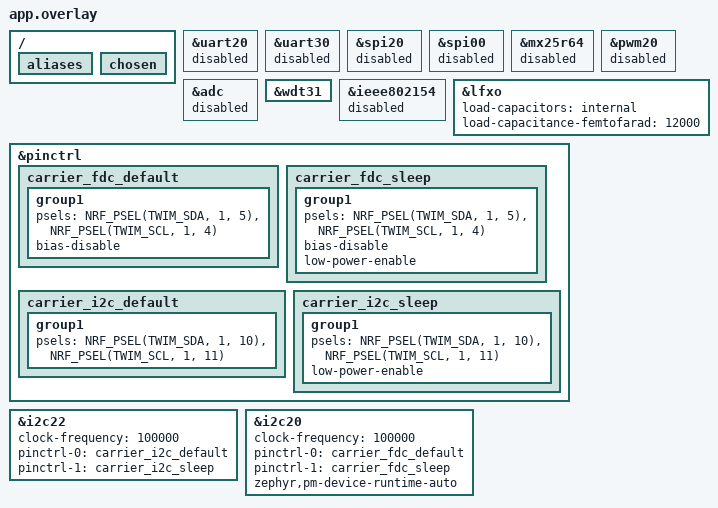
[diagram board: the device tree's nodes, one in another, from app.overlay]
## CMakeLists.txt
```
cmake_minimum_required(VERSION 3.20.0)
find_package(Zephyr REQUIRED HINTS $ENV{ZEPHYR_BASE})

# Production builds must opt in with a real signing key. The normal developer
# build intentionally keeps the SDK key so local builds remain reproducible,
# but this gate prevents that key from being used with the production profile.
if(DEFINED ENV{SENSOR_PRODUCTION_BUILD})
  if(NOT DEFINED CONFIG_MCUBOOT_SIGNATURE_KEY_FILE OR
     CONFIG_MCUBOOT_SIGNATURE_KEY_FILE STREQUAL "" OR
     CONFIG_MCUBOOT_SIGNATURE_KEY_FILE MATCHES "root-(rsa(-[0-9]+)?|ec(-p[0-9]+)?|ed25519)\\.pem$")
    message(FATAL_ERROR
      "SENSOR_PRODUCTION_BUILD requires CONFIG_MCUBOOT_SIGNATURE_KEY_FILE "
      "pointing to a protected non-SDK signing key")
  endif()
endif()

project(board_sensor)
target_sources(app PRIVATE src/main.c src/carrier.c src/bthome.c src/config.c src/config_service.c)
```

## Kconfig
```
mainmenu "Board sensor firmware"

source "Kconfig.zephyr"

config SENSOR_DEVELOPMENT
	bool "Development mode"
	default n
	help
		Use a short measurement cadence and a longer advertising window for bench work.

config SENSOR_CYCLE_SECONDS
	int "Normal measurement interval in seconds"
	default 60 if SENSOR_DEVELOPMENT
	default 900
	range 60 86400

config SENSOR_LOW_BATTERY_MV
	int "Low-battery threshold in millivolts"
	default 2500
	range 800 3300

config SENSOR_LOW_BATTERY_CYCLE_SECONDS
	int "Low-battery measurement interval in seconds"
	default 3600
	range 60 604800

config SENSOR_UV_RETRY_SECONDS
	int "Undervoltage/fault hibernate retry interval in seconds"
	default 60
	range 60 86400
	help
		Check recovery separately from the hourly low-battery measurement
		cadence. MCUboot checks voltage before image verification, sensing,
		or radio work; a restored supply must not remain silent for an hour.

config SENSOR_ADV_WINDOW_MS
	int "BLE advertising window in milliseconds"
	default 10000 if SENSOR_DEVELOPMENT
	default 5000
	range 5000 300000

config SENSOR_DEBUG_HOLD
	bool "Hold after measurement for debugger diagnostics"
	default n
	help
		Keep the CPU awake after the measurement so RTT can be read during bench work.

config SENSOR_OTA
	bool "Enable OTA maintenance image"
	default n
	help
		Build the MCUboot/MCUmgr maintenance image for the board. It keeps
		the boost rail in forced high-power mode, advertises a connectable SMP
		service, and stays awake for the update. Keep disabled in the normal
		battery beacon image.

config SENSOR_MOISTURE_CALIBRATED
	bool "Enable calibrated BTHome moisture objects"
	default y
	help
		Use the configured dry and wet single-ended capacitance endpoints.
		Leave disabled until the probe has been measured dry and wet.

config SENSOR_SENSE1_DRY_FF
	int "Dry SENSE1 capacitance in femtofarads"
	default 2655

config SENSOR_SENSE1_WET_FF
	int "Wet SENSE1 capacitance in femtofarads"
	default 5658

config SENSOR_SENSE2_DRY_FF
	int "Dry SENSE2 capacitance in femtofarads"
	default 2618

config SENSOR_SENSE2_WET_FF
	int "Wet SENSE2 capacitance in femtofarads"
	default 5571

config SENSOR_ADV_INTERVAL_MS
	int "Advertising event interval in milliseconds (multiple of 5)"
	default 500
	range 100 5000

config SENSOR_SESSION_SECONDS
	int "Maximum connected session duration in seconds"
	default 300
	range 30 900
```

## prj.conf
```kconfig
CONFIG_I2C=y
CONFIG_I2C_NRFX_TRANSFER_TIMEOUT=25
CONFIG_GPIO=y
CONFIG_WATCHDOG=y
CONFIG_REBOOT=y
CONFIG_POWEROFF=y
CONFIG_BT=y
CONFIG_BT_BROADCASTER=y
CONFIG_BT_PERIPHERAL=y
CONFIG_BT_OBSERVER=n
CONFIG_BT_DEVICE_NAME="Soil"

# The deployed sensor remains OTA-capable. A BLE connection during the normal
# advertising window holds the device awake while MCUmgr uploads the next
# signed image; an unconnected wake still returns to System OFF.
CONFIG_BOOTLOADER_MCUBOOT=y
CONFIG_FLASH=y
CONFIG_FLASH_MAP=y
CONFIG_STREAM_FLASH=y
CONFIG_IMG_MANAGER=y
CONFIG_MCUBOOT_IMG_MANAGER=y
CONFIG_MCUMGR=y
CONFIG_ZCBOR=y
CONFIG_MCUMGR_GRP_IMG=y
CONFIG_MCUMGR_GRP_OS=y
CONFIG_MCUMGR_TRANSPORT_BT=y
CONFIG_MCUMGR_TRANSPORT_BT_CONN_PARAM_CONTROL=y
CONFIG_MCUMGR_TRANSPORT_BT_REASSEMBLY=y
CONFIG_MCUMGR_TRANSPORT_NETBUF_SIZE=2475
CONFIG_MCUMGR_TRANSPORT_WORKQUEUE_STACK_SIZE=4608
CONFIG_BT_L2CAP_TX_MTU=498
CONFIG_BT_BUF_ACL_RX_SIZE=502
CONFIG_BT_BUF_ACL_TX_SIZE=502
CONFIG_BT_CTLR_DATA_LENGTH_MAX=251
CONFIG_SYSTEM_WORKQUEUE_STACK_SIZE=2304
CONFIG_HWINFO=y
CONFIG_SERIAL=n
CONFIG_UART_CONSOLE=n
CONFIG_MAIN_STACK_SIZE=2048
CONFIG_PM_DEVICE=y
CONFIG_PM_DEVICE_RUNTIME=y

# Configuration occupies the old 4 KB tail gap; MCUboot slots do not move.
CONFIG_ZMS=y
CONFIG_ZMS_DATA_CRC=y
CONFIG_BT_DEVICE_NAME_DYNAMIC=y
CONFIG_BT_DEVICE_NAME_MAX=11
CONFIG_BT_MAX_CONN=1
```

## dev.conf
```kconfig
CONFIG_SENSOR_DEVELOPMENT=y
CONFIG_SENSOR_CYCLE_SECONDS=60
CONFIG_SENSOR_ADV_WINDOW_MS=300000
CONFIG_SENSOR_MOISTURE_CALIBRATED=y
CONFIG_SENSOR_DEBUG_HOLD=n
CONFIG_BOOTLOADER_MCUBOOT=y
CONFIG_FLASH=y
CONFIG_FLASH_MAP=y
CONFIG_STREAM_FLASH=y
CONFIG_IMG_MANAGER=y
CONFIG_MCUBOOT_IMG_MANAGER=y
```

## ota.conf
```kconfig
CONFIG_SENSOR_OTA=y
CONFIG_MCUBOOT_IMGTOOL_SIGN_VERSION="0.2.6"
CONFIG_BOOTLOADER_MCUBOOT=y
CONFIG_FLASH=y
CONFIG_FLASH_MAP=y
CONFIG_IMG_MANAGER=y

CONFIG_BT=y
CONFIG_BT_PERIPHERAL=y
CONFIG_BT_BROADCASTER=y
CONFIG_BT_DEVICE_NAME="Soil-OTA"

CONFIG_NET_BUF=y
CONFIG_ZCBOR=y
CONFIG_CRC=y
CONFIG_STREAM_FLASH=y
CONFIG_MCUMGR=y
CONFIG_MCUMGR_GRP_IMG=y
CONFIG_MCUMGR_GRP_OS=y
CONFIG_MCUMGR_TRANSPORT_BT=y
CONFIG_MCUMGR_TRANSPORT_BT_CONN_PARAM_CONTROL=y
CONFIG_MCUMGR_TRANSPORT_BT_REASSEMBLY=y
CONFIG_MCUMGR_TRANSPORT_NETBUF_SIZE=2475
CONFIG_MCUMGR_TRANSPORT_WORKQUEUE_STACK_SIZE=4608

CONFIG_BT_L2CAP_TX_MTU=498
CONFIG_BT_BUF_ACL_RX_SIZE=502
CONFIG_BT_BUF_ACL_TX_SIZE=502
CONFIG_BT_CTLR_DATA_LENGTH_MAX=251
CONFIG_SYSTEM_WORKQUEUE_STACK_SIZE=2304
CONFIG_MAIN_STACK_SIZE=3072
CONFIG_LOG=y
CONFIG_LOG_MAX_LEVEL=3
```

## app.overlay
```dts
#include <zephyr/dt-bindings/pinctrl/nrf-pinctrl.h>
/ {
 /delete-node/ leds;
 /delete-node/ buttons;
 /delete-node/ pwmleds;
 aliases {
  /delete-property/ led0;
  /delete-property/ led1;
  /delete-property/ led2;
  /delete-property/ led3;
  /delete-property/ pwm-led0;
  /delete-property/ sw0;
  /delete-property/ sw1;
  /delete-property/ sw2;
  /delete-property/ sw3;
  /delete-property/ mcuboot-button0;
  /delete-property/ mcuboot-led0;
 };
 chosen {
  /delete-property/ zephyr,console;
  /delete-property/ zephyr,shell-uart;
  /delete-property/ zephyr,uart-mcumgr;
  /delete-property/ zephyr,bt-mon-uart;
  /delete-property/ zephyr,bt-c2h-uart;
 };
};
&uart20 { status = "disabled"; };
&uart30 { status = "disabled"; };
&spi20 { status = "disabled"; };
&spi00 { status = "disabled"; };
&mx25r64 { status = "disabled"; };
&pwm20 { status = "disabled"; };
&adc { status = "disabled"; };
&wdt31 { status = "okay"; };
&ieee802154 { status = "disabled"; };
&lfxo {
 load-capacitors = "internal";
 /* X1 CL=7 pF; provisional pin load, verify frequency on hardware. */
 load-capacitance-femtofarad = <12000>;
};
&pinctrl {
 carrier_fdc_default: carrier_fdc_default {
  group1 {
   psels = <NRF_PSEL(TWIM_SDA, 1, 5)>, <NRF_PSEL(TWIM_SCL, 1, 4)>;
   bias-disable;
  };
 };
 carrier_fdc_sleep: carrier_fdc_sleep {
  group1 {
   psels = <NRF_PSEL(TWIM_SDA, 1, 5)>, <NRF_PSEL(TWIM_SCL, 1, 4)>;
   bias-disable;
   low-power-enable;
  };
 };
 carrier_i2c_default: carrier_i2c_default {
  group1 { psels = <NRF_PSEL(TWIM_SDA, 1, 10)>, <NRF_PSEL(TWIM_SCL, 1, 11)>; };
 };
 carrier_i2c_sleep: carrier_i2c_sleep {
  group1 {
   psels = <NRF_PSEL(TWIM_SDA, 1, 10)>, <NRF_PSEL(TWIM_SCL, 1, 11)>;
   low-power-enable;
  };
 };
};
&i2c22 {
 status = "okay";
 clock-frequency = <100000>;
 pinctrl-0 = <&carrier_i2c_default>;
 pinctrl-1 = <&carrier_i2c_sleep>;
 pinctrl-names = "default", "sleep";
};

/* R36/R37 pull up only to +3V3_FDC_SW. Start suspended and release pins
 * between transfers, including failed transfers and before rail shutdown. */
&i2c20 {
 status = "okay";
 clock-frequency = <100000>;
 pinctrl-0 = <&carrier_fdc_default>;
 pinctrl-1 = <&carrier_fdc_sleep>;
 pinctrl-names = "default", "sleep";
 zephyr,pm-device-runtime-auto;
};
```

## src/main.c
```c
/* Real battery-powered sensor image. One cold boot per cycle. */
#include "carrier.h"
#include "bthome.h"
#include "config_service.h"
#include <string.h>
#include <zephyr/bluetooth/bluetooth.h>
#include <zephyr/bluetooth/conn.h>
#include <zephyr/mgmt/mcumgr/transport/smp_bt.h>
#include <zephyr/dfu/mcuboot.h>
#include <zephyr/drivers/hwinfo.h>
#include <zephyr/drivers/i2c.h>
#include <zephyr/drivers/timer/nrf_grtc_timer.h>
#include <zephyr/drivers/watchdog.h>
#include <zephyr/kernel.h>
#include <zephyr/pm/device.h>
#include <zephyr/pm/device_runtime.h>
#include <zephyr/sys/poweroff.h>
#include <zephyr/sys/reboot.h>

struct sensor_boot_trace {
    uint32_t magic;
    uint32_t boots;
    uint32_t stage;
    int32_t error;
    uint32_t last_failure_stage;
    int32_t last_failure_error;
    struct carrier_fault fault;
    struct carrier_sample sample;
    uint32_t wake_seconds;
};

static struct sensor_boot_trace sensor_trace __attribute__((section(".noinit")));
static struct carrier_fault cycle_fault;
static const struct carrier_bus *trace_bus;
static uint32_t reset_cause;
static uint8_t pmic_reset = 0xff, previous_stage = 0xff;

static void pmic_trace(uint8_t stage)
{
    if (trace_bus)
        (void)carrier_retained_stage(trace_bus, stage);
}

static void trace_boot(void)
{
    /* A new layout/magic must never interpret old or power-on SRAM as errors. */
    if (sensor_trace.magic != 0x53454e54u)
        sensor_trace = (struct sensor_boot_trace){.magic = 0x53454e54u};
    sensor_trace.boots++;
}

static void trace_stage(uint32_t stage, int error)
{
    pmic_trace(stage);
    sensor_trace.stage = stage;
    sensor_trace.error = error;
}

static void trace_failure(uint32_t stage, int error)
{
    trace_stage(stage, error);
    sensor_trace.last_failure_stage = stage;
    sensor_trace.last_failure_error = error;
    sensor_trace.fault = cycle_fault;
    printk("sensor failure stage=%u error=%d addr=0x%02x reg=0x%02x "
           "observed=0x%04x mask=0x%04x expected=0x%04x\n",
           (unsigned)stage, error, cycle_fault.address, cycle_fault.reg,
           cycle_fault.observed, cycle_fault.mask, cycle_fault.expected);
}

static uint16_t diagnostic_error(void)
{
    int64_t error = sensor_trace.last_failure_error;

    if (error < 0)
        error = -error;
    return error > UINT16_MAX ? UINT16_MAX : (uint16_t)error;
}

#if !CONFIG_SENSOR_OTA
static const struct device *sensor_wdt;
#endif

struct carrier_devices {
    const struct device *main;
    const struct device *fdc;
};

/* Runtime PM applies the no-pull, disconnected sleep pinctrl state. */
static int fdc_bus_is_asleep(const struct device *dev) {
    enum pm_device_state state;
    int rc = pm_device_state_get(dev, &state);
    if (rc)
        return rc;
    return pm_device_runtime_is_enabled(dev) && state == PM_DEVICE_STATE_SUSPENDED ? 0 : -EBUSY;
}

static int transfer(void *ctx, uint8_t address, const uint8_t *w, size_t nw, uint8_t *r,
                    size_t nr) {
    const struct carrier_devices *devices = ctx;
    const struct device *dev = address == 0x50 ? devices->fdc : devices->main;
    if (nw && nr)
        return i2c_write_read(dev, address, w, nw, r, nr);
    if (nw)
        return i2c_write(dev, w, nw, address);
    return i2c_read(dev, r, nr, address);
}
static void delay(void *ctx, unsigned ms) {
    (void)ctx;
    k_msleep(ms);
}
static char hex_digit(uint8_t v) {
    return v < 10 ? (char)('0' + v) : (char)('A' + v - 10);
}
static uint8_t battery_percent(uint16_t millivolts) {
    /* Provisional voltage-only estimate for the CR2032 prototype. */
    if (millivolts <= 2200)
        return 0;
    if (millivolts >= 3000)
        return 100;
    return (uint8_t)(((uint32_t)(millivolts - 2200) * 100U) / 800U);
}
#if !CONFIG_SENSOR_OTA
static int arm_watchdog(void) {
    const struct device *dev = DEVICE_DT_GET(DT_NODELABEL(wdt31));
    struct wdt_timeout_cfg cfg = {.window = {0, 15000}, .flags = WDT_FLAG_RESET_SOC};
    if (!device_is_ready(dev))
        return -ENODEV;
    int rc = wdt_install_timeout(dev, &cfg);
    if (rc < 0)
        return rc;
    rc = wdt_setup(dev, WDT_OPT_PAUSE_HALTED_BY_DBG);
    if (!rc)
        sensor_wdt = dev;
    return rc;
}

static void feed_watchdog(void)
{
    if (sensor_wdt)
        (void)wdt_feed(sensor_wdt, 0);
}
#else
static void feed_watchdog(void) { }
#endif
static int radio_window(const struct carrier_bus *bus, const struct carrier_sample *sample) {
    struct sensor_config config;
    sensor_settings_get(&config);
    trace_stage(70, 0);
    int rc = carrier_radio_start(bus);
    if (rc) {
        trace_failure(70, rc);
        return rc;
    }
    uint8_t id[16];
    bt_addr_le_t addr = {.type = BT_ADDR_LE_RANDOM};
    ssize_t n = hwinfo_get_device_id(id, sizeof(id));
    if (n < 6) {
        trace_failure(71, -EIO);
        return -EIO;
    }
    for (ssize_t i = 0; i < n; i++)
        addr.a.val[i % 6] ^= id[i];
    addr.a.val[5] |= 0xc0;
    rc = bt_id_create(&addr, NULL);
    if (rc < 0) {
        trace_failure(72, rc);
        return rc;
    }
    rc = bt_enable(NULL);
    if (rc) {
        trace_failure(73, rc);
        return rc;
    }
    char name[] = {
        'S', 'o', 'i', 'l', '-',
        hex_digit(addr.a.val[1] >> 4), hex_digit(addr.a.val[1] & 0x0f),
        hex_digit(addr.a.val[0] >> 4), hex_digit(addr.a.val[0] & 0x0f), 0,
    };
    const char *device_name = config.name[0] ? config.name : name;
    rc = bt_set_name(device_name);
    if (rc) return rc;
    /* BTHome v2 service data uses UUID FCD2, standard object IDs, and the
     * calibrated moisture values configured below. */
    uint8_t bthome[BOARD_BTHOME_PAYLOAD_LEN];
    struct board_bthome_values values = {
        .temperature_cc = sample->temperature_cc,
        .humidity_cpct = sample->humidity_cpct,
        .battery_pct = battery_percent(sample->battery_mv),
        .battery_mv = sample->battery_mv,
        .moisture1_cpct = sensor_moisture(sample->capacitance_ff[0], config.dry[0], config.wet[0]),
        .moisture2_cpct = sensor_moisture(sample->capacitance_ff[1], config.dry[1], config.wet[1]),
        .omit_moisture = !config.calibrated,
    };
    int payload_len = board_bthome_encode(&values, bthome, sizeof bthome);
    if (payload_len < 0) {
        trace_failure(74, -EINVAL);
        return -EINVAL;
    }
    const struct bt_data ad[] = {
        BT_DATA_BYTES(BT_DATA_FLAGS, BT_LE_AD_GENERAL | BT_LE_AD_NO_BREDR),
        BT_DATA(0x16, bthome, payload_len),
    };
    const struct bt_data sd[] = {
        BT_DATA(BT_DATA_NAME_COMPLETE, device_name, strlen(device_name)),
        /* SMP is in scan response; BTHome remains in the primary packet. */
        BT_DATA_BYTES(BT_DATA_UUID128_ALL, SMP_BT_SVC_UUID_VAL),
    };
    rc = bt_le_adv_start(BT_LE_ADV_PARAM(BT_LE_ADV_OPT_USE_IDENTITY |
                                         BT_LE_ADV_OPT_SCANNABLE |
                                         BT_LE_ADV_OPT_CONN,
                                         config.adv_ms * 8 / 5, config.adv_ms * 8 / 5,
                                         NULL),
                         ad, ARRAY_SIZE(ad), sd, ARRAY_SIZE(sd));
    if (rc) {
        trace_failure(75, rc);
        return rc;
    }
    trace_stage(76, sample->battery_mv);
    int64_t deadline = k_uptime_get() + config.window_ms;
    bool had_connection = false;
    while (k_uptime_get() < deadline || sensor_session_connected()) {
        uint16_t radio_battery_mv;
        rc = carrier_battery_read(bus, &radio_battery_mv);
        if (!rc && radio_battery_mv < CARRIER_MIN_BATTERY_MV)
            rc = -ERANGE;
        if (!rc)
            rc = carrier_watchdog_feed(bus);
        if (rc) {
            trace_failure(78, rc);
            sensor_session_disconnect();
            (void)bt_le_adv_stop();
            return rc;
        }
        feed_watchdog();
        sensor_settings_process();
        if (sensor_session_expired()) {
            sensor_session_disconnect();
            break;
        }
        if (sensor_session_connected()) had_connection = true;
        else if (had_connection) break;
        if (sensor_sample_requested()) {
            /* Foreground only; callbacks never touch I2C. Sampling remains
             * bounded by both watchdogs, with the FDC rail off afterwards. */
            struct carrier_sample fresh = {0};
            int measured = carrier_start(bus, &fresh);
            if (!measured) measured = carrier_measure(bus, &fresh);
            const struct carrier_devices *devices = bus->ctx;
            int off = fdc_bus_is_asleep(devices->fdc);
            if (!off && !measured) off = carrier_radio_start(bus);
            sensor_status_sample(&fresh, measured ? measured : off);
            if (off) {
                trace_failure(80, off);
                return off;
            }
            if (measured) {
                trace_failure(61, measured);
                sensor_session_disconnect();
                (void)bt_le_adv_stop();
                return measured;
            }
        }
        int64_t remaining = deadline - k_uptime_get();
        sensor_session_wait(sensor_session_connected() ? 1000 :
                            remaining > 1000 ? 1000 : remaining > 0 ? remaining : 0);
    }
    /* Finish an accepted save even if the client has just disconnected. */
    sensor_settings_process();
    feed_watchdog();
    rc = bt_le_adv_stop();
    if (rc != -EALREADY && rc)
        trace_failure(77, rc);
    else
        trace_stage(77, 0);
    return rc == -EALREADY ? 0 : rc;
}

#if CONFIG_SENSOR_OTA
static const struct bt_data ota_ad[] = {
    BT_DATA_BYTES(BT_DATA_FLAGS, BT_LE_AD_GENERAL | BT_LE_AD_NO_BREDR),
    BT_DATA_BYTES(BT_DATA_UUID128_ALL, SMP_BT_SVC_UUID_VAL),
};
static const struct bt_data ota_sd[] = {
    BT_DATA(BT_DATA_NAME_COMPLETE, CONFIG_BT_DEVICE_NAME,
            sizeof(CONFIG_BT_DEVICE_NAME) - 1),
};
static void ota_advertise(void) {
    int rc = bt_le_adv_start(BT_LE_ADV_CONN_FAST_1, ota_ad, ARRAY_SIZE(ota_ad),
                             ota_sd, ARRAY_SIZE(ota_sd));
    if (rc)
        printk("OTA advertising failed (%d)\n", rc);
    else
        printk("OTA ready: connect over BLE using MCUmgr/SMP\n");
}
static void ota_disconnected(struct bt_conn *conn, uint8_t reason) {
    ARG_UNUSED(conn);
    printk("OTA disconnected (reason 0x%02x)\n", reason);
    ota_advertise();
}
BT_CONN_CB_DEFINE(sensor_ota_conn_callbacks) = {
    .disconnected = ota_disconnected,
};
static int ota_identity(void) {
    uint8_t id[16];
    bt_addr_le_t addr = {.type = BT_ADDR_LE_RANDOM};
    ssize_t n = hwinfo_get_device_id(id, sizeof(id));
    if (n < 6)
        return -EIO;
    for (ssize_t i = 0; i < n; i++)
        addr.a.val[i % 6] ^= id[i];
    addr.a.val[5] |= 0xc0;
    return bt_id_create(&addr, NULL) < 0 ? -EIO : 0;
}
static int ota_run(const struct carrier_bus *bus) {
    int rc = carrier_ota_start(bus);
    if (rc)
        return rc;
    rc = ota_identity();
    if (rc)
        return rc;
    rc = bt_enable(NULL);
    if (rc)
        return rc;
    rc = boot_write_img_confirmed();
    if (rc)
        return rc;
    ota_advertise();
    printk("OTA maintenance active\n");
    for (;;) {
        sensor_settings_process();
        if (sensor_session_expired()) sensor_session_disconnect();
        sensor_session_wait(1000);
    }
    return 0;
}
#endif
static void power_backoff(const struct carrier_bus *bus, int error)
{
    /* Keep the failing operation in SCRATCHB across Hibernate. Replacing it
     * with the generic backoff stage would hide sensing and radio failures
     * when the PMIC removes power from the MCU's retained RAM. */
    if (sensor_trace.last_failure_stage != sensor_trace.stage ||
        sensor_trace.last_failure_error != error)
        trace_failure(84, error);
    sensor_trace.wake_seconds = CONFIG_SENSOR_UV_RETRY_SECONDS;
    /* Preserve the watchdog origin across the hibernate power cut so the
     * first recovery advertisement/status can distinguish these paths. */
    if (trace_bus && (reset_cause & RESET_WATCHDOG))
        (void)carrier_retained_stage(bus, 0xe1);
    else if (trace_bus && ((pmic_reset >> 1) & 15) == 5)
        (void)carrier_retained_stage(bus, 0xe2);
    int rc = trace_bus ? carrier_hibernate(bus, CONFIG_SENSOR_UV_RETRY_SECONDS) : -ENODEV;
    /* Normally VOUT disappears during the task write. If I2C failed or the
     * rail did not turn off, use the MCU's timed System OFF as a fallback.
     * Retained BLOCKED prevents sensor/radio attempts on a watchdog reset.
     * A PMIC that cannot be reached cannot be guaranteed to stop its timer. */
    k_msleep(20);
    if (trace_bus)
        (void)carrier_stop(bus);
    trace_stage(85, rc);
    int wake = z_nrf_grtc_wakeup_prepare((uint64_t)CONFIG_SENSOR_UV_RETRY_SECONDS *
                                       USEC_PER_SEC);
    if (wake) {
        sensor_trace.stage = 86;
        sensor_trace.error = wake;
    }
    /* Even if timed wake preparation fails, stay off instead of feeding a
     * reset loop. Recovery then requires an external wake or power cycle.
     * No timeout-dependent work is safe after GRTC preparation. */
    sys_poweroff();
}

int main(void) {
    trace_boot();
    trace_stage(1, 0);
    struct carrier_devices devices = {
        .main = DEVICE_DT_GET(DT_NODELABEL(i2c22)),
        .fdc = DEVICE_DT_GET(DT_NODELABEL(i2c20)),
    };
    struct carrier_bus bus = {&devices, transfer, delay, &cycle_fault};
    struct carrier_sample sample = {0};
    int rc = 0;
    if (!device_is_ready(devices.main) || !device_is_ready(devices.fdc))
        rc = -ENODEV;
    if (!rc)
        rc = fdc_bus_is_asleep(devices.fdc);
    if (device_is_ready(devices.main))
        trace_bus = &bus;
    if (rc)
        power_backoff(&bus, rc);

    uint8_t retained = 0;
    rc = carrier_retained_read(&bus, &retained, &previous_stage, &pmic_reset);
    if (!rc)
        rc = carrier_power_probe(&bus, &sample.battery_mv);
    (void)hwinfo_get_reset_cause(&reset_cause);
    (void)hwinfo_clear_reset_cause();
    sensor_status_diagnostics(reset_cause, pmic_reset, previous_stage,
                              sensor_trace.last_failure_stage, diagnostic_error());
    /* An interrupted attempt gets a full quiet interval even after voltage
     * rebounds. Once BLOCKED, use a higher voltage for recovery. SMP's explicit
     * software reboot at a healthy supply must still allow an OTA test boot;
     * normal error paths below never request immediate software reboots. */
    bool planned_reboot = (reset_cause & RESET_SOFTWARE) &&
                          sample.battery_mv >= CARRIER_RECOVER_BATTERY_MV;
    if (rc || (retained == CARRIER_POWER_ATTEMPT && !planned_reboot) ||
        !carrier_power_allowed(sample.battery_mv, retained))
        power_backoff(&bus, rc ? rc : -EAGAIN);
    rc = carrier_retained_state(&bus, CARRIER_POWER_ATTEMPT);
    if (rc)
        power_backoff(&bus, rc);
    uint8_t clear[] = {0xd1, 1};
    (void)transfer(&devices, 0x74, clear, 2, NULL, 0);
#if !CONFIG_SENSOR_OTA
    rc = arm_watchdog();
    if (rc)
        power_backoff(&bus, rc);
#endif
    int settings_rc = sensor_settings_init();
    if (settings_rc)
        printk("configuration load failed (%d); using build defaults\n", settings_rc);
#if CONFIG_SENSOR_OTA
    rc = ota_run(&bus);
    power_backoff(&bus, rc);
    return 0;
#else
    trace_stage(2, 0);
#endif
    trace_stage(40, 0);
    rc = carrier_start(&bus, &sample);
    bool power_ready = rc == 0;
    trace_stage(50, rc);
    if (rc)
        trace_failure(50, rc);
    if (!rc) {
        trace_stage(60, 0);
        rc = carrier_measure(&bus, &sample);
        if (rc)
            trace_failure(61, rc);
    }
    sensor_trace.sample = sample;
    sensor_status_sample(&sample, rc);
    int stop = fdc_bus_is_asleep(devices.fdc);
    if (!stop)
        stop = carrier_sensors_off(&bus);
    if (stop)
        power_backoff(&bus, stop);
    bool low_battery = sample.battery_mv < CARRIER_MIN_BATTERY_MV;
    if (rc || low_battery)
        power_backoff(&bus, rc ? rc : -ERANGE);
    if (power_ready) {
        rc = radio_window(&bus, &sample);
        if (rc)
            power_backoff(&bus, rc);
    }
    stop = carrier_stop(&bus);
    if (stop)
        power_backoff(&bus, stop);
    struct sensor_config config;
    sensor_settings_get(&config);
    uint32_t cycle_seconds = sensor_sleep_seconds(&config,
        sample.battery_mv < config.low_mv, k_uptime_get());
    sensor_trace.wake_seconds = cycle_seconds;
#if !CONFIG_SENSOR_OTA && defined(CONFIG_BOOTLOADER_MCUBOOT)
    if (!settings_rc && boot_write_img_confirmed())
        power_backoff(&bus, -EIO);
#endif
    rc = carrier_retained_state(&bus, CARRIER_POWER_CLEAN);
    if (rc)
        power_backoff(&bus, rc);
    trace_stage(83, 0);
    k_msleep(20);
    /* GRTC preparation disables kernel compare channels. Nothing that uses
     * I2C, delays, logging, or any kernel timeout may follow it. */
    int wake = z_nrf_grtc_wakeup_prepare((uint64_t)cycle_seconds * USEC_PER_SEC);
    if (wake) {
        sensor_trace.stage = 81;
        sensor_trace.error = wake;
        /* Fail closed: an external wake may be needed if no timer was armed. */
    }
    sys_poweroff();
    return 0;
}
```

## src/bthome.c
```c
#include "bthome.h"

#include <errno.h>

static size_t put_u16(uint8_t *p, size_t i, uint8_t object, uint16_t value)
{
    p[i++] = object;
    p[i++] = (uint8_t)value;
    p[i++] = (uint8_t)(value >> 8);
    return i;
}

static size_t put_u8(uint8_t *p, size_t i, uint8_t object, uint8_t value)
{
    p[i++] = object;
    p[i++] = value;
    return i;
}

int board_bthome_encode(const struct board_bthome_values *v,
                        uint8_t *p, size_t n)
{
    size_t i = 0;

    if (!v || !p || n < BOARD_BTHOME_PAYLOAD_LEN)
        return -EINVAL;

    /* BTHome v2, unencrypted. Multi-byte values are little endian. */
    p[i++] = 0xd2;
    p[i++] = 0xfc;
    p[i++] = 0x40;
    /* Objects are emitted in numerical order.  0x01 is battery percentage;
     * 0x0c is voltage in millivolts scaled by 0.001 V. */
    i = put_u8(p, i, 0x01, v->battery_pct);
    i = put_u16(p, i, 0x02, (uint16_t)v->temperature_cc);
    i = put_u16(p, i, 0x03, v->humidity_cpct);
    i = put_u16(p, i, 0x0c, v->battery_mv);
    if (!v->omit_moisture) {
        i = put_u16(p, i, 0x14, v->moisture1_cpct);
        i = put_u16(p, i, 0x14, v->moisture2_cpct);
    }
    return (int)i;
}
```

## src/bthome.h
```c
#ifndef BOARD_BTHOME_H
#define BOARD_BTHOME_H

#include <stddef.h>
#include <stdint.h>

struct board_bthome_values {
    int16_t temperature_cc;
    uint16_t humidity_cpct;
    uint8_t battery_pct;
    uint16_t battery_mv;
    uint16_t moisture1_cpct;
    uint16_t moisture2_cpct;
    uint16_t diagnostic_stage;
    uint16_t diagnostic_error;
};

/* UUID FCD2 + info + measurements + two diagnostic count objects. */
#define BOARD_BTHOME_PAYLOAD_LEN 26
#define BOARD_BTHOME_DIAGNOSTIC_LEN 9

int board_bthome_encode(const struct board_bthome_values *values,
                        uint8_t *payload, size_t payload_len);
/* Failed samples carry diagnostics only; zero is a valid sensor reading. */
int board_bthome_encode_diagnostic(uint16_t stage, uint16_t error,
                                  uint8_t *payload, size_t payload_len);

#endif
```

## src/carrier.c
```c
#include "carrier.h"
#include <errno.h>
static int fault(const struct carrier_bus *b, int error, uint8_t address, uint8_t reg,
                 uint16_t observed, uint16_t mask, uint16_t expected) {
    if (b->fault && !b->fault->error)
        *b->fault = (struct carrier_fault){error, address, reg, observed, mask, expected};
    return error;
}

static int transfer(const struct carrier_bus *b, uint8_t address, const uint8_t *w,
                    size_t nw, uint8_t *r, size_t nr) {
    int rc = b->transfer(b->ctx, address, w, nw, r, nr);
    if (rc < 0)
        return fault(b, rc, address, nw ? w[0] : 0, 0, 0, 0);
    return rc;
}
uint8_t carrier_crc(const uint8_t *d, size_t n) {
    uint8_t crc = 0xff;
    for (size_t i = 0; i < n; i++) {
        crc ^= d[i];
        for (int j = 0; j < 8; j++)
            crc = (crc & 0x80) ? (crc << 1) ^ 0x31 : crc << 1;
    }
    return crc;
}
#define TRY(expr)                                                                                  \
    do {                                                                                           \
        int rc = (expr);                                                                           \
        if (rc < 0)                                                                                \
            return rc;                                                                             \
    } while (0)
static int wr(const struct carrier_bus *b, uint8_t reg, uint8_t value) {
    uint8_t w[] = {reg, value};
    return transfer(b, 0x74, w, 2, 0, 0);
}
static int rd(const struct carrier_bus *b, uint8_t reg, uint8_t *value) {
    return transfer(b, 0x74, &reg, 1, value, 1);
}
static int checked(const struct carrier_bus *b, uint8_t reg, uint8_t value) {
    uint8_t v;
    TRY(wr(b, reg, value));
    TRY(rd(b, reg, &v));
    return v == value ? 0 : fault(b, -EIO, 0x74, reg, v, 0xff, value);
}
static int wait_pm(const struct carrier_bus *b, uint8_t reg, uint8_t mask, uint8_t value) {
    uint8_t v = 0;
    for (int i = 0; i < 30; i++) {
        TRY(rd(b, reg, &v));
        if ((v & mask) == value)
            return 0;
        b->delay_ms(b->ctx, 1);
    }
    return fault(b, -ETIMEDOUT, 0x74, reg, v, mask, value);
}
static int adc(const struct carrier_bus *b, uint8_t mode, uint16_t *mv) {
    uint8_t v, bit = mode == 4 ? 8 : 1;
    /* nPM2100 DS 7.1: a new conversion may only start when ADC is ready. */
    TRY(wait_pm(b, 0x9d, 3, 0));
    TRY(wr(b, 0x06, bit)); /* Clear stale ADC ready event before triggering. */
    TRY(checked(b, 0x91, mode));
    TRY(wr(b, 0x90, 1));
    TRY(wait_pm(b, 0x01, bit, bit));
    TRY(rd(b, mode == 4 ? 0x99 : 0x96, &v));
    *mv = mode == 4 ? 1800 + (1500 * (unsigned)v) / 256 : (3200 * (unsigned)v) / 256;
    return 0;
}
int carrier_watchdog_start(const struct carrier_bus *b, uint32_t seconds) {
    if (!seconds || seconds > 262144)
        return -EINVAL;
    TRY(wr(b, 0xb1, 1));
    TRY(wait_pm(b, 0xb7, 0xff, 0));
    TRY(checked(b, 0xd6, 1)); /* Also disable LDOSW on watchdog reset. */
    uint32_t ticks = seconds * 64 - 1;
    TRY(checked(b, 0xb4, ticks >> 16));
    TRY(checked(b, 0xb5, ticks >> 8));
    TRY(checked(b, 0xb6, ticks));
    TRY(checked(b, 0xb3, 2));
    return wr(b, 0xb0, 1);
}
int carrier_start(const struct carrier_bus *b, struct carrier_sample *s) {
    /* nPM2100 remains powered across MCU System OFF and watchdog resets. */
    TRY(carrier_sensors_off(b));
    TRY(carrier_watchdog_start(b, 20));
    TRY(adc(b, 0, &s->battery_mv));
    if (s->battery_mv < CARRIER_MIN_BATTERY_MV)
        return -ERANGE; /* Board input floor; no cell-capacity claim. */
    TRY(checked(b, 0x22, 30));
    TRY(checked(b, 0x23, 1)); /* 3.3 V */
    TRY(checked(b, 0x24, 1)); /* Force HP for sensor conversion accuracy. */
    TRY(wait_pm(b, 0x34, 7, 0)); /* Confirm actual converter state is HP. */
    b->delay_ms(b->ctx, 5);
    TRY(adc(b, 4, &s->output_mv));
    if (s->output_mv < 3150)
        return -ERANGE;
    TRY(checked(b, 0x6a, 5));    /* Load switch, forced HP, not default LDO. */
    TRY(checked(b, 0x6f, 0x14)); /* 40 mA load-switch OCP, retain LDO default. */
    TRY(checked(b, 0x6c, 1));
    TRY(checked(b, 0x69, 1));
    TRY(wait_pm(b, 0x6e, 0x16, 6));
    b->delay_ms(b->ctx, 5);
    return 0;
}
int carrier_ota_start(const struct carrier_bus *b) {
    /* OTA can last minutes: do not arm the 20-second PMIC watchdog or
     * enable the switched sensor rail. Keep only the radio supply on. */
    TRY(carrier_sensors_off(b));
    TRY(wr(b, 0xb1, 1));
    TRY(wait_pm(b, 0xb7, 0xff, 0));
    TRY(checked(b, 0x22, 30));
    TRY(checked(b, 0x23, 1));
    TRY(checked(b, 0x24, 1));
    TRY(wait_pm(b, 0x34, 7, 0));
    return 0;
}
static int fdc_read(const struct carrier_bus *b, uint8_t reg, uint16_t *v) {
    uint8_t r[2];
    TRY(transfer(b, 0x50, &reg, 1, r, 2));
    *v = ((uint16_t)r[0] << 8) | r[1];
    return 0;
}
static int fdc_write(const struct carrier_bus *b, uint8_t reg, uint16_t v) {
    uint8_t w[] = {reg, v >> 8, v};
    return transfer(b, 0x50, w, 3, 0, 0);
}
static int capacitance(const struct carrier_bus *b, unsigned ch, int32_t *ff, uint8_t *dac) {
    /* Only single-ended CAPDAC mode: this PCB physically ties SHLD1 to SHLD2. */
    for (unsigned d = 0; d < 32; d++) {
        TRY(fdc_write(b, 8, (ch << 13) | (4 << 10) | (d << 5)));
        TRY(fdc_write(b, 12, 0x480)); /* One measurement, 100 sps, no repeat. */
        unsigned i;
        uint16_t status = 0;
        for (i = 0; i < 30; i++) {
            TRY(fdc_read(b, 12, &status));
            if (status & 8)
                break;
            b->delay_ms(b->ctx, 1);
        }
        if (i == 30)
            return fault(b, -ETIMEDOUT, 0x50, 12, status, 8, 8);
        uint16_t hi, lo;
        TRY(fdc_read(b, 0, &hi));
        TRY(fdc_read(b, 1, &lo));
        uint32_t u = ((uint32_t)hi << 8) | (lo >> 8);
        int32_t raw = u & 0x800000 ? (int32_t)u - 0x1000000 : (int32_t)u;
        /* Keep 2 pF margin from the +/-15 pF specified measurement limits. */
        int32_t residual = (int64_t)raw * 1000 / 524288;
        if (residual > 13000)
            continue;
        if (residual < -13000)
            return -ERANGE;
        *ff = residual + (int32_t)d * 3125;
        *dac = d;
        return 0;
    }
    return -ERANGE;
}
int carrier_measure(const struct carrier_bus *b, struct carrier_sample *s) {
    uint16_t id;
    TRY(fdc_read(b, 0xfe, &id));
    if (id != 0x5449)
        return -ENODEV;
    TRY(fdc_read(b, 0xff, &id));
    if (id != 0x1004)
        return -ENODEV;
    TRY(capacitance(b, 0, &s->capacitance_ff[0], &s->capdac[0]));
    TRY(capacitance(b, 1, &s->capacitance_ff[1], &s->capdac[1]));
    const uint8_t cmd = 0xfd;
    uint8_t r[6]; /* No heater command exists here. */
    TRY(transfer(b, 0x44, &cmd, 1, 0, 0));
    b->delay_ms(b->ctx, 10);
    TRY(transfer(b, 0x44, 0, 0, r, 6));
    if (carrier_crc(r, 2) != r[2] || carrier_crc(r + 3, 2) != r[5])
        return -EBADMSG;
    uint32_t t = ((uint16_t)r[0] << 8) | r[1], h = ((uint16_t)r[3] << 8) | r[4];
    s->temperature_cc = -4500 + (17500 * t) / 65535;
    int rh = -600 + (12500 * h) / 65535;
    s->humidity_cpct = rh < 0 ? 0 : rh > 10000 ? 10000 : rh;
    TRY(adc(b, 0, &s->battery_mv));
    if (s->battery_mv < CARRIER_MIN_BATTERY_MV)
        return -ERANGE;
    return 0;
}
int carrier_sensors_off(const struct carrier_bus *b) {
    TRY(checked(b, 0x69, 0));
    /* STATUS.LDO (bit 0) is already zero while the load switch is ON.
     * Wait for both operating modes (HP/ULP) to clear. The observed disabled
     * load-switch status may retain SW (0x02); it must not retain HP/ULP. */
    return wait_pm(b, 0x6e, 0x0c, 0);
}
int carrier_watchdog_feed(const struct carrier_bus *b) {
    return wr(b, 0xb2, 1); /* TIMER.TASKS_KICK, DS 7.2.6.3. */
}
int carrier_radio_start(const struct carrier_bus *b) {
    uint16_t output_mv;
    TRY(carrier_sensors_off(b));
    TRY(checked(b, 0x24, 0)); /* Auto: allow HP on demand, LP/ULP between events. */
    TRY(adc(b, 4, &output_mv));
    /* This detects gross rail loss, not ripple or short radio transients. */
    return output_mv < 3150 ? -ERANGE : 0;
}
int carrier_stop(const struct carrier_bus *b) {
    /* Do not disarm recovery if I2C prevents safe shutdown. */
    TRY(carrier_sensors_off(b));
    TRY(checked(b, 0x24, 0)); /* Auto, LP/ULP allowed while MCU sleeps. */
    TRY(wr(b, 0xb1, 1));
    TRY(wait_pm(b, 0xb7, 0xff, 0));
    return 0;
}

int carrier_retained_read(const struct carrier_bus *b, uint8_t *state, uint8_t *stage,
                          uint8_t *reset) {
    TRY(rd(b, 0xd9, state));
    TRY(rd(b, 0xda, stage));
    return rd(b, 0xd5, reset);
}
int carrier_retained_state(const struct carrier_bus *b, uint8_t state) {
    uint8_t observed;
    TRY(wr(b, 0xd7, state));
    TRY(wr(b, 0xd8, 1));
    TRY(rd(b, 0xd9, &observed));
    return observed == state ? 0 : fault(b, -EIO, 0x74, 0xd9, observed, 255, state);
}
int carrier_retained_stage(const struct carrier_bus *b, uint8_t stage) {
    return checked(b, 0xda, stage);
}
int carrier_power_probe(const struct carrier_bus *b, uint16_t *battery_mv) {
    /* Run before settings, MCU watchdog, forced HP, sensors, or Bluetooth.
     * Stop an inherited PMIC boot/watchdog timer before attempting recovery. */
    TRY(wr(b, 0xb1, 1));
    TRY(wait_pm(b, 0xb7, 0xff, 0));
    TRY(carrier_sensors_off(b));
    TRY(checked(b, 0x24, 0));
    return adc(b, 0, battery_mv);
}
int carrier_hibernate(const struct carrier_bus *b, uint32_t seconds) {
    if (seconds < 1 || seconds > 262144)
        return -EINVAL;
    /* SCRATCHA is in the VBAT domain: survives MCU and PMIC power-cycle resets.
     * No flash writes at low voltage. Hibernate keeps BOOST alive in ULP and
     * removes VOUT; Hibernate_PT is unsuitable for a depleted input. */
    TRY(carrier_retained_state(b, CARRIER_POWER_BLOCKED));
    TRY(carrier_sensors_off(b));
    TRY(checked(b, 0x24, 0));
    TRY(wr(b, 0xb1, 1));
    TRY(wait_pm(b, 0xb7, 0xff, 0));
    uint32_t ticks = seconds * 64 - 1;
    TRY(checked(b, 0xb4, ticks >> 16));
    TRY(checked(b, 0xb5, ticks >> 8));
    TRY(checked(b, 0xb6, ticks));
    TRY(checked(b, 0xb3, 3));
    TRY(wr(b, 0xb0, 1));
    TRY(wait_pm(b, 0xb7, 0xff, 1));
    return wr(b, 0xc8, 1);
}
bool carrier_power_allowed(uint16_t mv, uint8_t retained) {
    return mv >= (retained == CARRIER_POWER_BLOCKED ? CARRIER_RECOVER_BATTERY_MV :
                                                        CARRIER_MIN_BATTERY_MV);
}

int carrier_battery_read(const struct carrier_bus *b, uint16_t *mv) {
    return adc(b, 0, mv);
}
```

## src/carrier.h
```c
#ifndef CARRIER_H
#define CARRIER_H
#include <stddef.h>
#include <stdbool.h>
#include <stdint.h>
/* Board policy, in PMIC ADC millivolts; cell sag still requires qualification. */
#define CARRIER_MIN_BATTERY_MV 1800
#define CARRIER_RECOVER_BATTERY_MV 2000
#define CARRIER_POWER_CLEAN 0xa0
#define CARRIER_POWER_ATTEMPT 0xa1
#define CARRIER_POWER_BLOCKED 0xa2
#define CARRIER_POWER_BOOTING 0xa3
/* A status timeout is distinct from a failed bus transfer. Kept by the caller
 * so subsequent shutdown transactions cannot erase the original evidence. */
struct carrier_fault {
    int error;
    uint8_t address, reg;
    uint16_t observed, mask, expected;
};
/* Callbacks must bound each bus transaction. No concurrent users of this bus. */
struct carrier_bus {
    void *ctx;
    int (*transfer)(void *, uint8_t, const uint8_t *, size_t, uint8_t *, size_t);
    void (*delay_ms)(void *, unsigned);
    struct carrier_fault *fault;
};
struct carrier_sample {
    uint16_t battery_mv, output_mv;
    int16_t temperature_cc;
    uint16_t humidity_cpct;
    int32_t capacitance_ff[2];
    uint8_t capdac[2];
};
int carrier_start(const struct carrier_bus *, struct carrier_sample *);
int carrier_ota_start(const struct carrier_bus *);
int carrier_measure(const struct carrier_bus *, struct carrier_sample *);
/* Leave BOOST and the watchdog on while disconnecting the sensor supply. */
int carrier_sensors_off(const struct carrier_bus *);
/* Bench trial: automatic BOOST during BLE, with sensors off and watchdog armed. */
int carrier_radio_start(const struct carrier_bus *);
/* Feed only while the foreground radio/OTA loop is making progress. */
int carrier_watchdog_feed(const struct carrier_bus *);
int carrier_watchdog_start(const struct carrier_bus *, uint32_t seconds);
/* Only stops PMIC watchdog after the switched rail is confirmed disabled. */
int carrier_stop(const struct carrier_bus *);
uint8_t carrier_crc(const uint8_t *, size_t);
int carrier_retained_read(const struct carrier_bus *, uint8_t *, uint8_t *, uint8_t *);
int carrier_retained_state(const struct carrier_bus *, uint8_t);
int carrier_retained_stage(const struct carrier_bus *, uint8_t);
int carrier_battery_read(const struct carrier_bus *, uint16_t *);
int carrier_power_probe(const struct carrier_bus *, uint16_t *);
int carrier_hibernate(const struct carrier_bus *, uint32_t seconds);
bool carrier_power_allowed(uint16_t mv, uint8_t retained);
#endif
```

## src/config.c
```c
#include "config.h"
#include <errno.h>
#include <string.h>
static uint16_t get16(const uint8_t *p) { return p[0] | (uint16_t)p[1] << 8; }
static uint32_t get32(const uint8_t *p) { return get16(p) | (uint32_t)get16(p + 2) << 16; }
static void put16(uint8_t *p, uint16_t v) { p[0] = v; p[1] = v >> 8; }
static void put32(uint8_t *p, uint32_t v) { put16(p, v); put16(p + 2, v >> 16); }
int sensor_config_validate(const struct sensor_config *c)
{
    if (c->cycle_s < 60 || c->cycle_s > 86400 || c->low_cycle_s < c->cycle_s ||
        c->low_cycle_s > 604800 || c->window_ms < 5000 || c->window_ms > 300000 ||
        c->window_ms > (uint64_t)c->cycle_s * 500 ||
        c->adv_ms < 100 || c->adv_ms > 5000 || c->adv_ms % 5 ||
        c->window_ms < (uint32_t)c->adv_ms * 5 ||
        c->session_s < 30 || c->session_s > 900 || c->low_mv < 800 || c->low_mv > 3300)
        return -EINVAL;
    size_t n = 0;
    while (n <= SENSOR_NAME_MAX && c->name[n]) {
        if (c->name[n] < 32 || c->name[n] > 126)
            return -EINVAL;
        n++;
    }
    if (n > SENSOR_NAME_MAX)
        return -EINVAL;
    for (unsigned i = 0; i < 2; i++) {
        if (c->dry[i] < -15000 || c->dry[i] > 115000 ||
            c->wet[i] < -15000 || c->wet[i] > 115000 || c->dry[i] == c->wet[i])
            return -EINVAL;
    }
    return 0;
}
void sensor_config_encode(const struct sensor_config *c, uint8_t p[SENSOR_CONFIG_SIZE])
{
    memset(p, 0, SENSOR_CONFIG_SIZE);
    p[0] = 1;
    p[1] = c->calibrated;
    p[2] = strlen(c->name);
    put32(p + 4, c->cycle_s); put32(p + 8, c->low_cycle_s); put32(p + 12, c->window_ms);
    put16(p + 16, c->adv_ms); put16(p + 18, c->session_s); put16(p + 20, c->low_mv);
    put32(p + 24, c->dry[0]); put32(p + 28, c->wet[0]);
    put32(p + 32, c->dry[1]); put32(p + 36, c->wet[1]);
    memcpy(p + 40, c->name, p[2]);
}
int sensor_config_decode(struct sensor_config *c, const uint8_t *p, size_t len)
{
    if (len != SENSOR_CONFIG_SIZE || p[0] != 1 || p[1] > 1 || p[2] > SENSOR_NAME_MAX ||
        p[3] || p[22] || p[23])
        return -EINVAL;
    for (unsigned i = 40 + p[2]; i < SENSOR_CONFIG_SIZE; i++)
        if (p[i]) return -EINVAL;
    struct sensor_config v = {
        .cycle_s = get32(p + 4), .low_cycle_s = get32(p + 8), .window_ms = get32(p + 12),
        .adv_ms = get16(p + 16), .session_s = get16(p + 18), .low_mv = get16(p + 20),
        .dry = {(int32_t)get32(p + 24), (int32_t)get32(p + 32)},
        .wet = {(int32_t)get32(p + 28), (int32_t)get32(p + 36)}, .calibrated = p[1],
    };
    memcpy(v.name, p + 40, p[2]);
    /* Reject embedded NULs so each configuration has one canonical encoding. */
    if (strlen(v.name) != p[2] || sensor_config_validate(&v)) return -EINVAL;
    *c = v;
    return 0;
}
uint16_t sensor_moisture(int32_t ff, int32_t dry, int32_t wet)
{
    int64_t span = (int64_t)wet - dry;
    if (!span) return 0;
    int64_t v = ((int64_t)ff - dry) * 10000 / span;
    return v < 0 ? 0 : v > 10000 ? 10000 : (uint16_t)v;
}
uint32_t sensor_sleep_seconds(const struct sensor_config *c, bool low, uint64_t elapsed_ms)
{
    uint32_t interval = low ? c->low_cycle_s : c->cycle_s;
    uint64_t elapsed_s = (elapsed_ms + 999) / 1000;
    /* Never spin through cold boots after a long configuration/OTA session. */
    return elapsed_s >= interval ? interval : interval - (uint32_t)elapsed_s;
}
uint32_t sensor_config_crc(const uint8_t *data, size_t len)
{
    uint32_t crc = UINT32_MAX;
    for (size_t i = 0; i < len; i++) {
        crc ^= data[i];
        for (unsigned b = 0; b < 8; b++)
            crc = (crc >> 1) ^ (0xedb88320u & (0u - (crc & 1)));
    }
    return ~crc;
}
int sensor_config_command(struct config_transaction *t, const uint8_t *p, size_t len,
                          struct sensor_config *ready)
{
    if (!len || len > 20) return -EINVAL;
    if (p[0] == 1 && len == 1) {
        *t = (struct config_transaction){.active = true};
        return 0;
    }
    if (!t->active) return -EINVAL;
    if (p[0] == 2 && len >= 3 && p[1] + len - 2 <= SENSOR_CONFIG_SIZE) {
        for (size_t i = 2; i < len; i++) {
            t->data[p[1] + i - 2] = p[i];
            t->received |= UINT64_C(1) << (p[1] + i - 2);
        }
        return 0;
    }
    if (p[0] == 3 && len == 5 && t->received == UINT64_MAX &&
        get32(p + 1) == sensor_config_crc(t->data, sizeof(t->data))) {
        t->active = false;
        return sensor_config_decode(ready, t->data, sizeof(t->data)) ? -EINVAL : 1;
    }
    return -EINVAL;
}
```

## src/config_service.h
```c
#ifndef SENSOR_CONFIG_SERVICE_H
#define SENSOR_CONFIG_SERVICE_H
#include "config.h"
#include "carrier.h"
int sensor_settings_init(void);
void sensor_settings_get(struct sensor_config *out);
/* Called only by foreground; no storage or I2C work in Bluetooth callbacks. */
void sensor_settings_process(void);
void sensor_status_sample(const struct carrier_sample *sample, int error);
bool sensor_sample_requested(void);
bool sensor_session_connected(void);
bool sensor_session_expired(void);
void sensor_session_disconnect(void);
void sensor_session_wait(uint32_t milliseconds);
void sensor_status_diagnostics(uint32_t reset, uint8_t pmic, uint8_t previous, uint8_t stage, uint8_t error);
#endif
```
